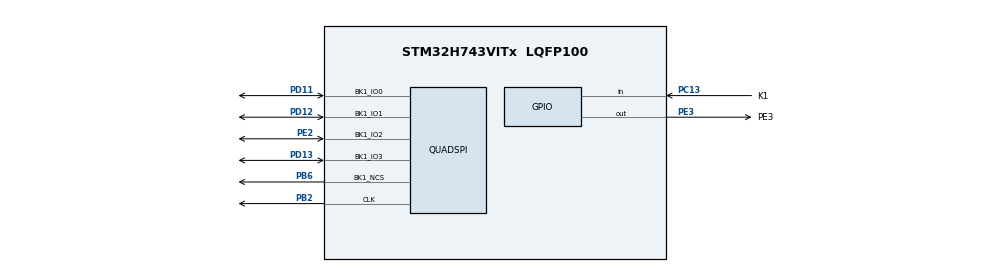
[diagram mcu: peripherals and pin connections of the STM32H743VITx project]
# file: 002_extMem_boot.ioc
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CORTEX_M7.CPU_DCache=Enabled
CORTEX_M7.CPU_ICache=Enabled
CORTEX_M7.default_mode_Activation=1
Mcu.Family=STM32H7
Mcu.Name=STM32H743VITx
Mcu.Package=LQFP100
NVIC.PriorityGroup=NVIC_PRIORITYGROUP_4
PA13\ (JTMS/SWDIO).Mode=Serial_Wire
PA13\ (JTMS/SWDIO).Signal=DEBUG_JTMS-SWDIO
PA14\ (JTCK/SWCLK).Mode=Serial_Wire
PA14\ (JTCK/SWCLK).Signal=DEBUG_JTCK-SWCLK
PB2.GPIO_Speed=GPIO_SPEED_FREQ_VERY_HIGH
PB2.Mode=Single Bank 1
PB2.Signal=QUADSPI_CLK
PB6.GPIO_Speed=GPIO_SPEED_FREQ_VERY_HIGH
PB6.Mode=Single Bank 1
PB6.Signal=QUADSPI_BK1_NCS
PC13.GPIO_Label=K1
PC13.Signal=GPIO_Input
PC14-OSC32_IN\ (OSC32_IN).Mode=LSE-External-Oscillator
PC14-OSC32_IN\ (OSC32_IN).Signal=RCC_OSC32_IN
PC15-OSC32_OUT\ (OSC32_OUT).Mode=LSE-External-Oscillator
PC15-OSC32_OUT\ (OSC32_OUT).Signal=RCC_OSC32_OUT
PD11.GPIO_Speed=GPIO_SPEED_FREQ_VERY_HIGH
PD11.Mode=Single Bank 1
PD11.Signal=QUADSPI_BK1_IO0
PD12.GPIO_Speed=GPIO_SPEED_FREQ_VERY_HIGH
PD12.Mode=Single Bank 1
PD12.Signal=QUADSPI_BK1_IO1
PD13.GPIO_Speed=GPIO_SPEED_FREQ_VERY_HIGH
PD13.Mode=Single Bank 1
PD13.Signal=QUADSPI_BK1_IO3
PE2.GPIO_Speed=GPIO_SPEED_FREQ_VERY_HIGH
PE2.Mode=Single Bank 1
PE2.Signal=QUADSPI_BK1_IO2
PE3.GPIO_Label=PE3
PE3.Signal=GPIO_Output
PH0-OSC_IN\ (PH0).Mode=HSE-External-Oscillator
PH0-OSC_IN\ (PH0).Signal=RCC_OSC_IN
PH1-OSC_OUT\ (PH1).Mode=HSE-External-Oscillator
PH1-OSC_OUT\ (PH1).Signal=RCC_OSC_OUT
ProjectManager.HeapSize=0x200
ProjectManager.StackSize=0x400
ProjectManager.TargetToolchain=STM32CubeIDE
QUADSPI.ChipSelectHighTime=QSPI_CS_HIGH_TIME_8_CYCLE
QUADSPI.ClockMode=QSPI_CLOCK_MODE_3
QUADSPI.FifoThreshold=32
QUADSPI.FlashSize=23-1
QUADSPI.SampleShifting=QSPI_SAMPLE_SHIFTING_HALFCYCLE
RCC.ADCFreq_Value=200000000
RCC.APB1Freq_Value=120000000
RCC.APB2Freq_Value=120000000
RCC.APB3Freq_Value=120000000
RCC.APB4Freq_Value=120000000
RCC.CortexFreq_Value=240000000
RCC.DIVM1=5
RCC.DIVM2=2
RCC.DIVN1=96
RCC.DIVN2=32
RCC.DIVQ1=1
RCC.HCLKFreq_Value=120000000
RCC.HPRE=RCC_HCLK_DIV2
RCC.PLL2FRACN=0
RCC.PLL3FRACN=0
RCC.PLLFRACN=0
RCC.PLLSourceVirtual=RCC_PLLSOURCE_HSE
RCC.PWR_Regulator_Voltage_Scale=PWR_REGULATOR_VOLTAGE_SCALE2
RCC.SYSCLKFreq_VALUE=240000000
RCC.SYSCLKSource=RCC_SYSCLKSOURCE_PLLCLK
RCC.USBFreq_Value=480000000
VP_MEMORYMAP_VS_MEMORYMAP.Mode=CurAppReg
VP_RTC_VS_RTC_Activate.Mode=RTC_Enabled
board=custom

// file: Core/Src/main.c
/* USER CODE BEGIN Header */
/**
  ******************************************************************************
  * @file           : main.c
  * @brief          : Main program body
  ******************************************************************************
  * @attention
  *
  * Copyright (c) 2025 STMicroelectronics.
  * All rights reserved.
  *
  * This software is licensed under terms that can be found in the LICENSE file
  * in the root directory of this software component.
  * If no LICENSE file comes with this software, it is provided AS-IS.
  *
  ******************************************************************************
  */
/* USER CODE END Header */
#include "main.h"

/* USER CODE BEGIN Includes */
#include "w25qxx_qspi.h"
/* USER CODE END Includes */

/* USER CODE BEGIN PTD */
#define W25Qxx_TEST              (0)
#define APPLICATION_ADDRESS      QSPI_BASE
#define ISP_ADDRESS              (0x1FF09800UL)
typedef  void (*pFunction)(void);
/* USER CODE END PTD */

QSPI_HandleTypeDef hqspi;

RTC_HandleTypeDef hrtc;

/* USER CODE BEGIN PV */
pFunction JumpToApplication;
/* USER CODE END PV */

void SystemClock_Config(void);
static void MPU_Config(void);
static void MX_GPIO_Init(void);
static void MX_QUADSPI_Init(void);
static void MX_RTC_Init(void);

int main(void)
{

  /* MPU Configuration--------------------------------------------------------*/
  MPU_Config();

  /* Enable the CPU Cache */

  /* Enable I-Cache---------------------------------------------------------*/
  SCB_EnableICache();

  /* Enable D-Cache---------------------------------------------------------*/
  SCB_EnableDCache();

  /* MCU Configuration--------------------------------------------------------*/

  /* Reset of all peripherals, Initializes the Flash interface and the Systick. */
  HAL_Init();

  /* Configure the system clock */
  SystemClock_Config();

  /* Initialize all configured peripherals */
  MX_GPIO_Init();
  MX_QUADSPI_Init();
  MX_RTC_Init();

  /* Infinite loop */
  while (1)
  {

  }
}

void SystemClock_Config(void)
{
  RCC_OscInitTypeDef RCC_OscInitStruct = {0};
  RCC_ClkInitTypeDef RCC_ClkInitStruct = {0};

  /** Supply configuration update enable
  */
  HAL_PWREx_ConfigSupply(PWR_LDO_SUPPLY);

  /** Configure the main internal regulator output voltage
  */
  __HAL_PWR_VOLTAGESCALING_CONFIG(PWR_REGULATOR_VOLTAGE_SCALE2);

  while(!__HAL_PWR_GET_FLAG(PWR_FLAG_VOSRDY)) {}

  /** Initializes the RCC Oscillators according to the specified parameters
  * in the RCC_OscInitTypeDef structure.
  */
  RCC_OscInitStruct.OscillatorType = RCC_OSCILLATORTYPE_LSI|RCC_OSCILLATORTYPE_HSE;
  RCC_OscInitStruct.HSEState = RCC_HSE_ON;
  RCC_OscInitStruct.LSIState = RCC_LSI_ON;
  RCC_OscInitStruct.PLL.PLLState = RCC_PLL_ON;
  RCC_OscInitStruct.PLL.PLLSource = RCC_PLLSOURCE_HSE;
  RCC_OscInitStruct.PLL.PLLM = 5;
  RCC_OscInitStruct.PLL.PLLN = 96;
  RCC_OscInitStruct.PLL.PLLP = 2;
  RCC_OscInitStruct.PLL.PLLQ = 1;
  RCC_OscInitStruct.PLL.PLLR = 2;
  RCC_OscInitStruct.PLL.PLLRGE = RCC_PLL1VCIRANGE_2;
  RCC_OscInitStruct.PLL.PLLVCOSEL = RCC_PLL1VCOWIDE;
  RCC_OscInitStruct.PLL.PLLFRACN = 0;
  if (HAL_RCC_OscConfig(&RCC_OscInitStruct) != HAL_OK)
  {
    Error_Handler();
  }

  /** Initializes the CPU, AHB and APB buses clocks
  */
  RCC_ClkInitStruct.ClockType = RCC_CLOCKTYPE_HCLK|RCC_CLOCKTYPE_SYSCLK
                              |RCC_CLOCKTYPE_PCLK1|RCC_CLOCKTYPE_PCLK2
                              |RCC_CLOCKTYPE_D3PCLK1|RCC_CLOCKTYPE_D1PCLK1;
  RCC_ClkInitStruct.SYSCLKSource = RCC_SYSCLKSOURCE_PLLCLK;
  RCC_ClkInitStruct.SYSCLKDivider = RCC_SYSCLK_DIV1;
  RCC_ClkInitStruct.AHBCLKDivider = RCC_HCLK_DIV2;
  RCC_ClkInitStruct.APB3CLKDivider = RCC_APB3_DIV1;
  RCC_ClkInitStruct.APB1CLKDivider = RCC_APB1_DIV1;
  RCC_ClkInitStruct.APB2CLKDivider = RCC_APB2_DIV1;
  RCC_ClkInitStruct.APB4CLKDivider = RCC_APB4_DIV1;

  if (HAL_RCC_ClockConfig(&RCC_ClkInitStruct, FLASH_LATENCY_2) != HAL_OK)
  {
    Error_Handler();
  }
}

static void MX_QUADSPI_Init(void)
{

  /* QUADSPI parameter configuration*/
  hqspi.Instance = QUADSPI;
  hqspi.Init.ClockPrescaler = 255;
  hqspi.Init.FifoThreshold = 32;
  hqspi.Init.SampleShifting = QSPI_SAMPLE_SHIFTING_HALFCYCLE;
  hqspi.Init.FlashSize = 23-1;
  hqspi.Init.ChipSelectHighTime = QSPI_CS_HIGH_TIME_8_CYCLE;
  hqspi.Init.ClockMode = QSPI_CLOCK_MODE_3;
  hqspi.Init.FlashID = QSPI_FLASH_ID_1;
  hqspi.Init.DualFlash = QSPI_DUALFLASH_DISABLE;
  if (HAL_QSPI_Init(&hqspi) != HAL_OK)
  {
    Error_Handler();
  }

}

static void MX_RTC_Init(void)
{

  /** Initialize RTC Only
  */
  hrtc.Instance = RTC;
  hrtc.Init.HourFormat = RTC_HOURFORMAT_24;
  hrtc.Init.AsynchPrediv = 127;
  hrtc.Init.SynchPrediv = 255;
  hrtc.Init.OutPut = RTC_OUTPUT_DISABLE;
  hrtc.Init.OutPutPolarity = RTC_OUTPUT_POLARITY_HIGH;
  hrtc.Init.OutPutType = RTC_OUTPUT_TYPE_OPENDRAIN;
  hrtc.Init.OutPutRemap = RTC_OUTPUT_REMAP_NONE;
  if (HAL_RTC_Init(&hrtc) != HAL_OK)
  {
    Error_Handler();
  }

}

static void MX_GPIO_Init(void)
{
  GPIO_InitTypeDef GPIO_InitStruct = {0};

  /* GPIO Ports Clock Enable */
  __HAL_RCC_GPIOE_CLK_ENABLE();
  __HAL_RCC_GPIOC_CLK_ENABLE();
  __HAL_RCC_GPIOH_CLK_ENABLE();
  __HAL_RCC_GPIOB_CLK_ENABLE();
  __HAL_RCC_GPIOD_CLK_ENABLE();
  __HAL_RCC_GPIOA_CLK_ENABLE();

  /*Configure GPIO pin Output Level */
  HAL_GPIO_WritePin(PE3_GPIO_Port, PE3_Pin, GPIO_PIN_RESET);

  /*Configure GPIO pin : PE3_Pin */
  GPIO_InitStruct.Pin = PE3_Pin;
  GPIO_InitStruct.Mode = GPIO_MODE_OUTPUT_PP;
  GPIO_InitStruct.Pull = GPIO_NOPULL;
  GPIO_InitStruct.Speed = GPIO_SPEED_FREQ_LOW;
  HAL_GPIO_Init(PE3_GPIO_Port, &GPIO_InitStruct);

  /*Configure GPIO pin : K1_Pin */
  GPIO_InitStruct.Pin = K1_Pin;
  GPIO_InitStruct.Mode = GPIO_MODE_INPUT;
  GPIO_InitStruct.Pull = GPIO_NOPULL;
  HAL_GPIO_Init(K1_GPIO_Port, &GPIO_InitStruct);

}

 /* MPU Configuration */

void MPU_Config(void)
{
  MPU_Region_InitTypeDef MPU_InitStruct = {0};

  /* Disables the MPU */
  HAL_MPU_Disable();

  /** Initializes and configures the Region and the memory to be protected
  */
  MPU_InitStruct.Enable = MPU_REGION_ENABLE;
  MPU_InitStruct.Number = MPU_REGION_NUMBER0;
  MPU_InitStruct.BaseAddress = 0x0;
  MPU_InitStruct.Size = MPU_REGION_SIZE_4GB;
  MPU_InitStruct.SubRegionDisable = 0x87;
  MPU_InitStruct.TypeExtField = MPU_TEX_LEVEL0;
  MPU_InitStruct.AccessPermission = MPU_REGION_NO_ACCESS;
  MPU_InitStruct.DisableExec = MPU_INSTRUCTION_ACCESS_DISABLE;
  MPU_InitStruct.IsShareable = MPU_ACCESS_SHAREABLE;
  MPU_InitStruct.IsCacheable = MPU_ACCESS_NOT_CACHEABLE;
  MPU_InitStruct.IsBufferable = MPU_ACCESS_NOT_BUFFERABLE;

  HAL_MPU_ConfigRegion(&MPU_InitStruct);
  /* Enables the MPU */
  HAL_MPU_Enable(MPU_PRIVILEGED_DEFAULT);

}

void Error_Handler(void)
{
  __disable_irq();
  while (1)
  {
  }
}
